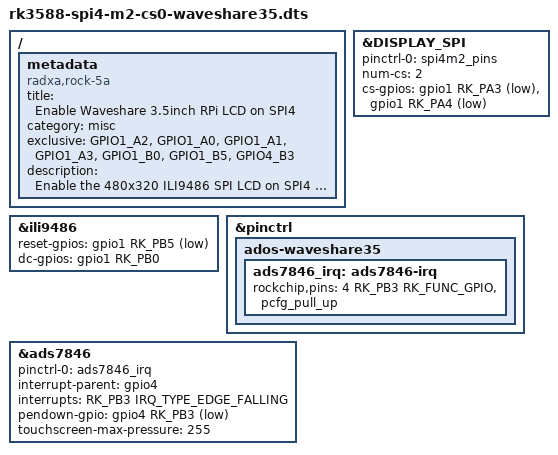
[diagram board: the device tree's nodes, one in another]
// SPDX-License-Identifier: GPL-2.0-or-later
/*
 * Activate the 480x320 ILI9486 SPI LCD on the SPI4 controller's M2 pad
 * mux. On boards that route SPI4_M2 onto the 40-pin expansion header at
 * the same physical pin positions as the Raspberry Pi puts SPI0 (Rock 5A
 * / Rock 5C / Rock 5D), this lets a Pi-style 3.5" LCD HAT plug in
 * directly. Touch is enabled.
 *
 * Polarity note: the XPT2046/ADS7846 PENIRQ output is open-drain
 * active-low with a ~50 kohm internal chip-side pull-up. Combined with
 * the Rockchip-side pcfg_pull_up from the pinctrl group below, the
 * line idles HIGH at VCC and only drops to LOW during finger contact.
 * pendown-gpio is GPIO_ACTIVE_LOW so gpiolib reads "pen down" when
 * the electrical level is LOW. Every working Pi-canonical Waveshare
 * overlay (swkim01/waveshare-dtoverlays, goodtft/LCD-show,
 * marcin-chwedczuk/waveshare-35A-raspberry-pi-64-driver) ships
 * ACTIVE_LOW, as do Rock 5B reports on the Radxa forum.
 *
 * An earlier ACTIVE_HIGH revision of this overlay (lifted from a
 * Radxa Rock 3B template that was itself copied from a vendor
 * reference using a different touch chip) caused the driver's
 * ads7846_get_pendown_state() to read "pen permanently down" at idle
 * and "pen up" on press, so the driver never armed the falling-edge
 * IRQ. /proc/interrupts ads7846 stayed at 0 across all CPUs and
 * across reboots, verified on Rock 5C Lite. Do not flip back to
 * ACTIVE_HIGH without an end-to-end IRQ-counter increment proof.
 *
 * Pinmux note: the PENIRQ pin also needs an explicit pinctrl group
 * that puts gpio4 PB3 into RK_FUNC_GPIO with pcfg_pull_up. Without
 * it, /sys/kernel/debug/pinctrl reports "(MUX UNCLAIMED)" and the
 * line bias is undefined.
 */

#define DISPLAY_SPI spi4
#include "waveshare35-lcd.dtsi"

/ {
    metadata {
        title = "Enable Waveshare 3.5inch RPi LCD on SPI4";
        compatible = "radxa,rock-5a", "radxa,rock-5c", "radxa,rock-5d";
        category = "misc";
        exclusive = "GPIO1_A2", "GPIO1_A0", "GPIO1_A1", "GPIO1_A3", "GPIO1_B0", "GPIO1_B5", "GPIO4_B3";
        description = "Enable the 480x320 ILI9486 SPI LCD on SPI4 with ADS7846 resistive touch.";
    };
};


&DISPLAY_SPI {
    pinctrl-0 = <&spi4m2_pins>;
    num-cs = <2>;
    cs-gpios = <&gpio1 RK_PA3 GPIO_ACTIVE_LOW
                &gpio1 RK_PA4 GPIO_ACTIVE_LOW>;
};

&ili9486 {
    reset-gpios = <&gpio1 RK_PB5 GPIO_ACTIVE_LOW>;
    dc-gpios = <&gpio1 RK_PB0 GPIO_ACTIVE_HIGH>;
};

&pinctrl {
    ados-waveshare35 {
        ads7846_irq: ads7846-irq {
            rockchip,pins = <4 RK_PB3 RK_FUNC_GPIO &pcfg_pull_up>;
        };
    };
};

&ads7846 {
    status = "okay";
    pinctrl-names = "default";
    pinctrl-0 = <&ads7846_irq>;
    interrupt-parent = <&gpio4>;
    interrupts = <RK_PB3 IRQ_TYPE_EDGE_FALLING>;
    pendown-gpio = <&gpio4 RK_PB3 GPIO_ACTIVE_LOW>;
    touchscreen-max-pressure = <255>;
};
